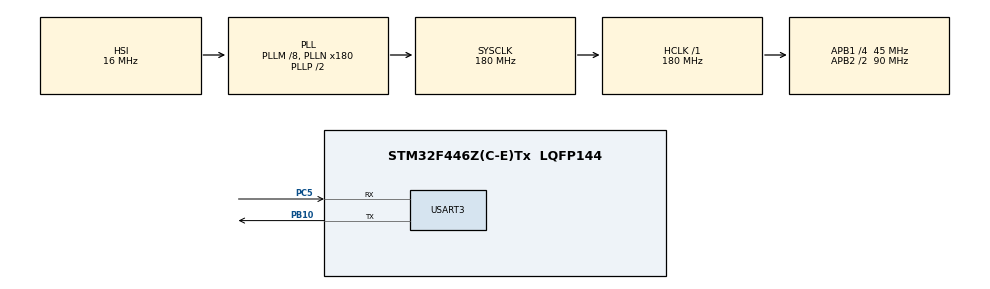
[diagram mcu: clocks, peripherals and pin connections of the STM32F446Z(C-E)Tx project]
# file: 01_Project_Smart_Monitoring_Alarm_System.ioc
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FREERTOS.BinarySemaphores01=AlarmSemaphore,Dynamic,NULL,Depleted;ResetSemaphore,Dynamic,NULL,Depleted
FREERTOS.Events01=abnormalflags,Dynamic,NULL
FREERTOS.Mutexes01=ConfigparamsMutex,Dynamic,NULL,Available
FREERTOS.Queues01=RawData,4,Raw_Data,0,Dynamic,NULL,NULL;CommandQueue,4,Command,0,Dynamic,NULL,NULL
FREERTOS.Tasks01=AcquisitionTask,24,128,StartAcquisitionTask,Default,NULL,Dynamic,NULL,NULL;ProcessingTask,32,128,StartProcessingTask,Default,NULL,Dynamic,NULL,NULL;AlarmTask,40,128,StartAlarmTask,Default,NULL,Dynamic,NULL,NULL;ConfigurationTa,16,128,StartConfigurationTask,Default,NULL,Dynamic,NULL,NULL;StatusTask,16,128,StartStatusTask,Default,NULL,Dynamic,NULL,NULL
FREERTOS.configUSE_NEWLIB_REENTRANT=1
Mcu.Family=STM32F4
Mcu.Name=STM32F446Z(C-E)Tx
Mcu.Package=LQFP144
NVIC.PriorityGroup=NVIC_PRIORITYGROUP_4
NVIC.TIM6_DAC_IRQn=true\:15\:0\:false\:false\:true\:false\:false\:true\:true
NVIC.TimeBase=TIM6_DAC_IRQn
NVIC.TimeBaseIP=TIM6
PB10.Mode=Asynchronous
PB10.Signal=USART3_TX
PC5.Mode=Asynchronous
PC5.Signal=USART3_RX
ProjectManager.HeapSize=0x200
ProjectManager.StackSize=0x400
ProjectManager.TargetToolchain=STM32CubeIDE
RCC.48MHZClocksFreq_Value=24000000
RCC.AHBFreq_Value=180000000
RCC.APB1CLKDivider=RCC_HCLK_DIV4
RCC.APB1Freq_Value=45000000
RCC.APB1TimFreq_Value=90000000
RCC.APB2CLKDivider=RCC_HCLK_DIV2
RCC.APB2Freq_Value=90000000
RCC.APB2TimFreq_Value=180000000
RCC.CortexFreq_Value=180000000
RCC.HCLKFreq_Value=180000000
RCC.HSE_VALUE=8000000
RCC.HSI_VALUE=16000000
RCC.PLLM=8
RCC.PLLMUL=RCC_PLL_MUL9
RCC.PLLN=180
RCC.PLLQ=7
RCC.PRESCALERUSB=RCC_USBCLKSOURCE_PLL_DIV1_5
RCC.SYSCLKFreq_VALUE=180000000
RCC.SYSCLKSource=RCC_SYSCLKSOURCE_PLLCLK
RCC.SYSCLKSourceVirtual=RCC_SYSCLKSOURCE_PLLCLK
RCC.USBFreq_Value=51428571.428571425
RCC.VCOOutputFreq_Value=360000000
USART3.VirtualMode=VM_ASYNC
VP_FREERTOS_VS_CMSIS_V2.Mode=CMSIS_V2
VP_SYS_VS_tim6.Mode=TIM6
board=NUCLEO-F446ZE

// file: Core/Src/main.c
/* USER CODE BEGIN Header */
/**
  ******************************************************************************
  * @file           : main.c
  * @brief          : Main program body
  ******************************************************************************
  * @attention
  *
  * Copyright (c) 2026 STMicroelectronics.
  * All rights reserved.
  *
  * This software is licensed under terms that can be found in the LICENSE file
  * in the root directory of this software component.
  * If no LICENSE file comes with this software, it is provided AS-IS.
  *
  ******************************************************************************
  */
/* USER CODE END Header */
#include "main.h"
#include "cmsis_os.h"

/* USER CODE BEGIN Includes */
#define Temperature_Flag (1U<<0)
#define Battery_Flag	(1U<<1)
#define Pressure_Flag	(1U<<2)
#define ACQUISITION_ENABLE_FLAG  (1U << 0)
/* USER CODE END Includes */

/* USER CODE BEGIN PTD */
typedef struct{
	uint32_t temperature;
	uint32_t pressure;
	uint32_t battery;
	uint32_t sample_number;
}Raw_Data;

typedef struct{
	uint32_t bat_threshold;
	uint32_t temp_threshold;
	uint32_t press_threshold;
}Sensor_Threshold;

typedef enum{
	CMD_RESET,
	CMD_SET_TEMP,
	CMD_SET_BAT,
	CMD_SET_PRE
}Command_Type;

typedef struct{
	Command_Type type;
	uint32_t value;
}Command;
/* USER CODE END PTD */

UART_HandleTypeDef huart3;

/* Definitions for AcquisitionTask */
osThreadId_t AcquisitionTaskHandle;
const osThreadAttr_t AcquisitionTask_attributes = {
  .name = "AcquisitionTask",
  .stack_size = 128 * 4,
  .priority = (osPriority_t) osPriorityNormal,
};
/* Definitions for ProcessingTask */
osThreadId_t ProcessingTaskHandle;
const osThreadAttr_t ProcessingTask_attributes = {
  .name = "ProcessingTask",
  .stack_size = 128 * 4,
  .priority = (osPriority_t) osPriorityAboveNormal,
};
/* Definitions for AlarmTask */
osThreadId_t AlarmTaskHandle;
const osThreadAttr_t AlarmTask_attributes = {
  .name = "AlarmTask",
  .stack_size = 128 * 4,
  .priority = (osPriority_t) osPriorityHigh,
};
/* Definitions for ConfigurationTa */
osThreadId_t ConfigurationTaHandle;
const osThreadAttr_t ConfigurationTa_attributes = {
  .name = "ConfigurationTa",
  .stack_size = 128 * 4,
  .priority = (osPriority_t) osPriorityBelowNormal,
};
/* Definitions for StatusTask */
osThreadId_t StatusTaskHandle;
const osThreadAttr_t StatusTask_attributes = {
  .name = "StatusTask",
  .stack_size = 128 * 4,
  .priority = (osPriority_t) osPriorityBelowNormal,
};
/* Definitions for RawData */
osMessageQueueId_t RawDataHandle;
const osMessageQueueAttr_t RawData_attributes = {
  .name = "RawData"
};
/* Definitions for CommandQueue */
osMessageQueueId_t CommandQueueHandle;
const osMessageQueueAttr_t CommandQueue_attributes = {
  .name = "CommandQueue"
};
/* Definitions for ConfigparamsMutex */
osMutexId_t ConfigparamsMutexHandle;
const osMutexAttr_t ConfigparamsMutex_attributes = {
  .name = "ConfigparamsMutex"
};
/* Definitions for AlarmSemaphore */
osSemaphoreId_t AlarmSemaphoreHandle;
const osSemaphoreAttr_t AlarmSemaphore_attributes = {
  .name = "AlarmSemaphore"
};
/* Definitions for ResetSemaphore */
osSemaphoreId_t ResetSemaphoreHandle;
const osSemaphoreAttr_t ResetSemaphore_attributes = {
  .name = "ResetSemaphore"
};
/* Definitions for abnormalflags */
osEventFlagsId_t abnormalflagsHandle;
const osEventFlagsAttr_t abnormalflags_attributes = {
  .name = "abnormalflags"
};
/* USER CODE BEGIN PV */
Sensor_Threshold thresholds = {
    .bat_threshold = 20,
    .temp_threshold = 95,
    .press_threshold = 90
};
volatile uint32_t current_alarm_state = 0;
/* USER CODE END PV */

void SystemClock_Config(void);
static void MX_GPIO_Init(void);
static void MX_USART3_UART_Init(void);
void StartAcquisitionTask(void *argument);
void StartProcessingTask(void *argument);
void StartAlarmTask(void *argument);
void StartConfigurationTask(void *argument);
void StartStatusTask(void *argument);

int main(void)
{

  /* MCU Configuration--------------------------------------------------------*/

  /* Reset of all peripherals, Initializes the Flash interface and the Systick. */
  HAL_Init();

  /* Configure the system clock */
  SystemClock_Config();

  /* Initialize all configured peripherals */
  MX_GPIO_Init();
  MX_USART3_UART_Init();

  /* Init scheduler */
  osKernelInitialize();
  /* Create the mutex(es) */
  /* creation of ConfigparamsMutex */
  ConfigparamsMutexHandle = osMutexNew(&ConfigparamsMutex_attributes);

  /* Create the semaphores(s) */
  /* creation of AlarmSemaphore */
  AlarmSemaphoreHandle = osSemaphoreNew(1, 0, &AlarmSemaphore_attributes);

  /* creation of ResetSemaphore */
  ResetSemaphoreHandle = osSemaphoreNew(1, 0, &ResetSemaphore_attributes);

  /* Create the queue(s) */
  /* creation of RawData */
  RawDataHandle = osMessageQueueNew (4, sizeof(Raw_Data), &RawData_attributes);

  /* creation of CommandQueue */
  CommandQueueHandle = osMessageQueueNew (4, sizeof(Command), &CommandQueue_attributes);

  /* Create the thread(s) */
  /* creation of AcquisitionTask */
  AcquisitionTaskHandle = osThreadNew(StartAcquisitionTask, NULL, &AcquisitionTask_attributes);

  /* creation of ProcessingTask */
  ProcessingTaskHandle = osThreadNew(StartProcessingTask, NULL, &ProcessingTask_attributes);

  /* creation of AlarmTask */
  AlarmTaskHandle = osThreadNew(StartAlarmTask, NULL, &AlarmTask_attributes);

  /* creation of ConfigurationTa */
  ConfigurationTaHandle = osThreadNew(StartConfigurationTask, NULL, &ConfigurationTa_attributes);

  /* creation of StatusTask */
  StatusTaskHandle = osThreadNew(StartStatusTask, NULL, &StatusTask_attributes);

  /* creation of abnormalflags */
  abnormalflagsHandle = osEventFlagsNew(&abnormalflags_attributes);

  /* USER CODE BEGIN RTOS_EVENTS */
  /* add events, ... */
  osEventFlagsSet(abnormalflagsHandle, ACQUISITION_ENABLE_FLAG);
  /* USER CODE END RTOS_EVENTS */

  /* Start scheduler */
  osKernelStart();

  /* We should never get here as control is now taken by the scheduler */

  /* Infinite loop */
  while (1)
  {

  }
}

void SystemClock_Config(void)
{
  RCC_OscInitTypeDef RCC_OscInitStruct = {0};
  RCC_ClkInitTypeDef RCC_ClkInitStruct = {0};

  /** Configure the main internal regulator output voltage
  */
  __HAL_RCC_PWR_CLK_ENABLE();
  __HAL_PWR_VOLTAGESCALING_CONFIG(PWR_REGULATOR_VOLTAGE_SCALE1);

  /** Initializes the RCC Oscillators according to the specified parameters
  * in the RCC_OscInitTypeDef structure.
  */
  RCC_OscInitStruct.OscillatorType = RCC_OSCILLATORTYPE_HSI;
  RCC_OscInitStruct.HSIState = RCC_HSI_ON;
  RCC_OscInitStruct.HSICalibrationValue = RCC_HSICALIBRATION_DEFAULT;
  RCC_OscInitStruct.PLL.PLLState = RCC_PLL_ON;
  RCC_OscInitStruct.PLL.PLLSource = RCC_PLLSOURCE_HSI;
  RCC_OscInitStruct.PLL.PLLM = 8;
  RCC_OscInitStruct.PLL.PLLN = 180;
  RCC_OscInitStruct.PLL.PLLP = RCC_PLLP_DIV2;
  RCC_OscInitStruct.PLL.PLLQ = 7;
  RCC_OscInitStruct.PLL.PLLR = 2;
  if (HAL_RCC_OscConfig(&RCC_OscInitStruct) != HAL_OK)
  {
    Error_Handler();
  }

  /** Activate the Over-Drive mode
  */
  if (HAL_PWREx_EnableOverDrive() != HAL_OK)
  {
    Error_Handler();
  }

  /** Initializes the CPU, AHB and APB buses clocks
  */
  RCC_ClkInitStruct.ClockType = RCC_CLOCKTYPE_HCLK|RCC_CLOCKTYPE_SYSCLK
                              |RCC_CLOCKTYPE_PCLK1|RCC_CLOCKTYPE_PCLK2;
  RCC_ClkInitStruct.SYSCLKSource = RCC_SYSCLKSOURCE_PLLCLK;
  RCC_ClkInitStruct.AHBCLKDivider = RCC_SYSCLK_DIV1;
  RCC_ClkInitStruct.APB1CLKDivider = RCC_HCLK_DIV4;
  RCC_ClkInitStruct.APB2CLKDivider = RCC_HCLK_DIV2;

  if (HAL_RCC_ClockConfig(&RCC_ClkInitStruct, FLASH_LATENCY_5) != HAL_OK)
  {
    Error_Handler();
  }
}

static void MX_USART3_UART_Init(void)
{

  huart3.Instance = USART3;
  huart3.Init.BaudRate = 115200;
  huart3.Init.WordLength = UART_WORDLENGTH_8B;
  huart3.Init.StopBits = UART_STOPBITS_1;
  huart3.Init.Parity = UART_PARITY_NONE;
  huart3.Init.Mode = UART_MODE_TX_RX;
  huart3.Init.HwFlowCtl = UART_HWCONTROL_NONE;
  huart3.Init.OverSampling = UART_OVERSAMPLING_16;
  if (HAL_UART_Init(&huart3) != HAL_OK)
  {
    Error_Handler();
  }

}

static void MX_GPIO_Init(void)
{

  /* GPIO Ports Clock Enable */
  __HAL_RCC_GPIOC_CLK_ENABLE();
  __HAL_RCC_GPIOB_CLK_ENABLE();

}

void StartAcquisitionTask(void *argument)
{
  /* USER CODE BEGIN 5 */
	Raw_Data raw;
	uint32_t bat=95;
	uint32_t temp=25;
	uint32_t press=35;
	uint32_t sample=0;
	osStatus_t status;

  /* Infinite loop */
  for(;;)
  {
	osEventFlagsWait(abnormalflagsHandle, ACQUISITION_ENABLE_FLAG, osFlagsNoClear|osFlagsWaitAny, osWaitForever);
	status=osSemaphoreAcquire(ResetSemaphoreHandle, 0);
	if(status==osOK)
	{
		 bat=95;
		 temp=25;
		 press=35;
		 sample=0;
	}

	bat--;temp++;press++;sample++;
	raw.battery = bat;
	raw.temperature = temp;
	raw.pressure = press;
	raw.sample_number = sample;

	osMessageQueuePut(RawDataHandle, &raw, 0, osWaitForever);
	osDelay(500);
  }
  /* USER CODE END 5 */
}

void StartProcessingTask(void *argument)
{
  /* USER CODE BEGIN StartProcessingTask */
	Raw_Data raw;

	uint32_t l_bat_threshold;
	uint32_t l_temp_threshold;
	uint32_t l_press_threshold;
    uint32_t new_alarm_state;

  /* Infinite loop */
  for(;;)
  {
    osMessageQueueGet(RawDataHandle, &raw, 0, osWaitForever);
    osMutexAcquire(ConfigparamsMutexHandle, osWaitForever);
	l_bat_threshold =thresholds.bat_threshold;
	l_temp_threshold =thresholds.temp_threshold;
	l_press_threshold=thresholds.press_threshold;
    osMutexRelease(ConfigparamsMutexHandle);
    new_alarm_state = 0;
    if(l_bat_threshold>raw.battery)
    	new_alarm_state |= Battery_Flag;
    if(l_temp_threshold<raw.temperature)
    	 new_alarm_state |= Temperature_Flag;
    if(l_press_threshold<raw.pressure)
    	new_alarm_state |= Pressure_Flag;
    if(new_alarm_state != current_alarm_state)
   {
	   current_alarm_state = new_alarm_state;
	   osSemaphoreRelease(AlarmSemaphoreHandle);
   }
  }
  /* USER CODE END StartProcessingTask */
}

void StartAlarmTask(void *argument)
{
  /* USER CODE BEGIN StartAlarmTask */

  /* Infinite loop */
  for(;;)
  {
	  osSemaphoreAcquire(AlarmSemaphoreHandle, osWaitForever);
	  switch(current_alarm_state)
	  {
	  	  case 0x00:
	  		osEventFlagsSet(abnormalflagsHandle, ACQUISITION_ENABLE_FLAG);
			  break;
	      case 0x01:
	    	  osEventFlagsSet(abnormalflagsHandle, ACQUISITION_ENABLE_FLAG);
	          break;
	      case 0x02:
	    	  osEventFlagsSet(abnormalflagsHandle, ACQUISITION_ENABLE_FLAG);
	          break;
	      case 0x03:
	    	  osEventFlagsSet(abnormalflagsHandle, ACQUISITION_ENABLE_FLAG);
	          break;
	      case 0x04:
	    	  osEventFlagsSet(abnormalflagsHandle, ACQUISITION_ENABLE_FLAG);
	          break;
	      case 0x05:
	    	  osEventFlagsClear(abnormalflagsHandle, ACQUISITION_ENABLE_FLAG);
	          break;
	      case 0x06:
	    	  osEventFlagsClear(abnormalflagsHandle, ACQUISITION_ENABLE_FLAG);
	          break;
	      case 0x07:
	    	  osEventFlagsClear(abnormalflagsHandle, ACQUISITION_ENABLE_FLAG);
	          break;
	  }
  }
  /* USER CODE END StartAlarmTask */
}

void StartConfigurationTask(void *argument)
{
  /* USER CODE BEGIN StartConfigurationTask */
	Command cmd;
	osMutexAcquire(ConfigparamsMutexHandle, osWaitForever);
	uint32_t l_bat_threshold =thresholds.bat_threshold;
	uint32_t l_temp_threshold =thresholds.temp_threshold;
	uint32_t l_press_threshold=thresholds.press_threshold;
	osMutexRelease(ConfigparamsMutexHandle);
  /* Infinite loop */
  for(;;)
  {
	  osMessageQueueGet(CommandQueueHandle, &cmd, 0, osWaitForever);
	  switch(cmd.type)
	  {
	  	  case CMD_RESET:
	  		osSemaphoreRelease(ResetSemaphoreHandle);
	  		osEventFlagsSet(abnormalflagsHandle,ACQUISITION_ENABLE_FLAG);
	  		break;
	  	  case CMD_SET_TEMP:
	  		l_temp_threshold=cmd.value;
	  		break;
	  	  case CMD_SET_BAT:
	  		l_bat_threshold=cmd.value;
	  		break;
	  	  case CMD_SET_PRE:
	  		l_press_threshold=cmd.value;
	  		break;
	  }
	  osMutexAcquire(ConfigparamsMutexHandle, osWaitForever);
	  thresholds.bat_threshold=l_bat_threshold;
	  thresholds.press_threshold=l_press_threshold;
	  thresholds.temp_threshold=l_temp_threshold;
	  osMutexRelease(ConfigparamsMutexHandle);
  }
  /* USER CODE END StartConfigurationTask */
}

void StartStatusTask(void *argument)
{
  /* USER CODE BEGIN StartStatusTask */
    Command cmd;
    osDelay(3000);

    cmd.type = CMD_SET_TEMP;
	cmd.value = 40;
	osMessageQueuePut(CommandQueueHandle,&cmd,0,osWaitForever);
	osDelay(3000);
	cmd.type = CMD_SET_PRE;
	cmd.value = 50;
	osMessageQueuePut(CommandQueueHandle,&cmd,0,osWaitForever);
	osDelay(3000);
	cmd.type = CMD_RESET;
	cmd.value = 0;
	osMessageQueuePut(CommandQueueHandle,&cmd,0,osWaitForever);
	osDelay(3000);
  /* Infinite loop */
  for(;;)
  {
	  osDelay(osWaitForever);
  }
  /* USER CODE END StartStatusTask */
}

void HAL_TIM_PeriodElapsedCallback(TIM_HandleTypeDef *htim)
{
  if (htim->Instance == TIM6)
  {
    HAL_IncTick();
  }
}

void Error_Handler(void)
{
  __disable_irq();
  while (1)
  {
  }
}
